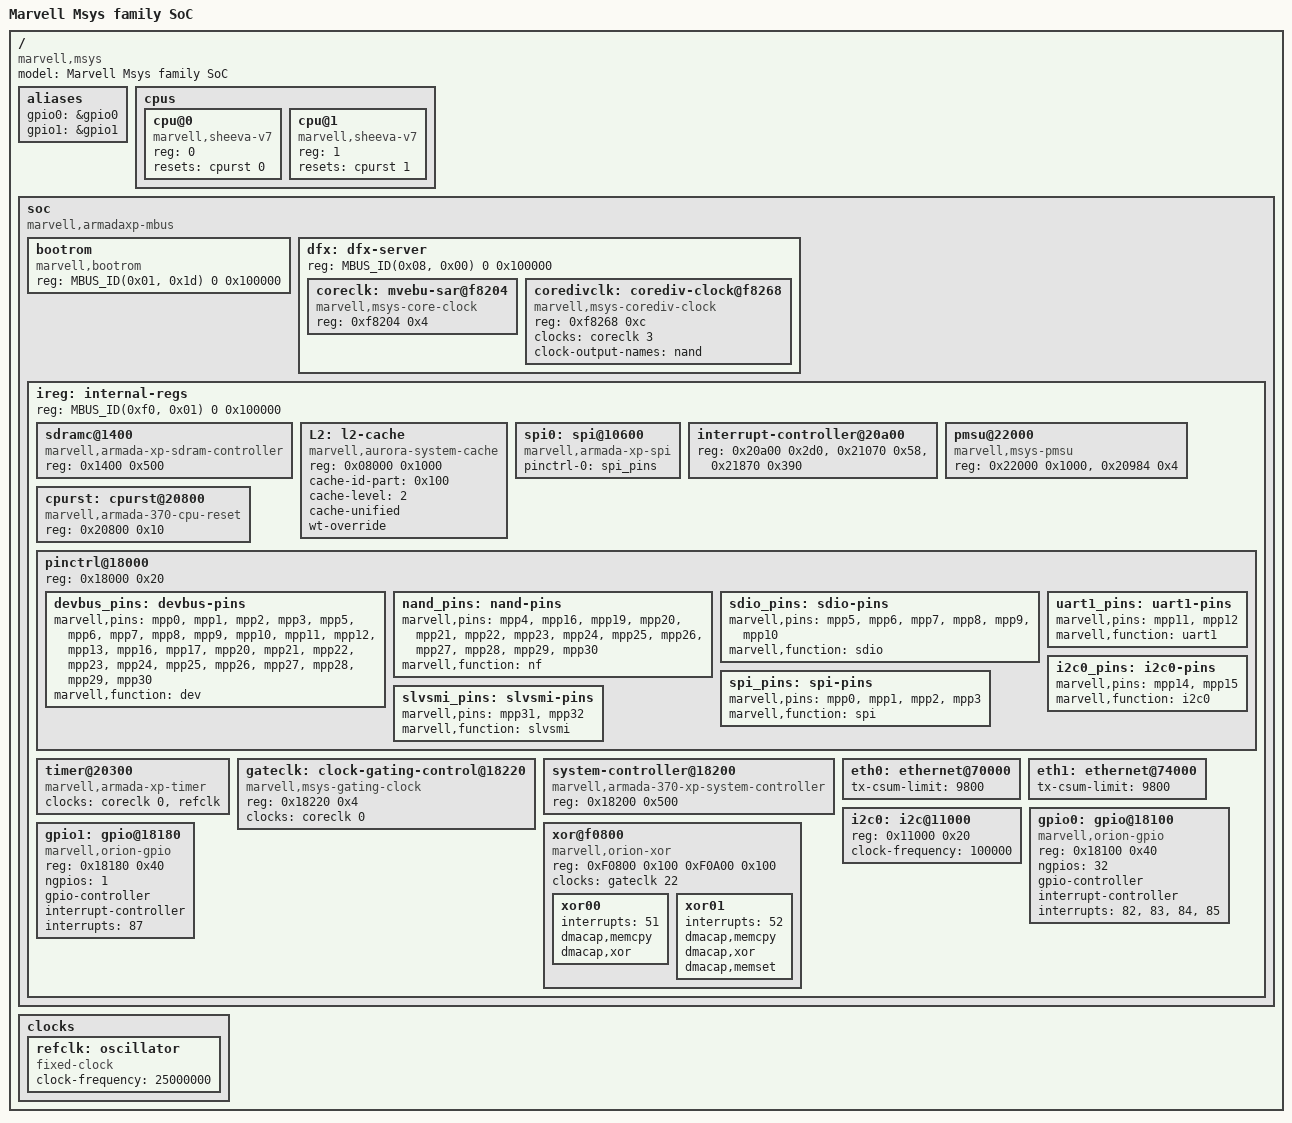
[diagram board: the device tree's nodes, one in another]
/*
 * Device Tree Include file for Marvell Msys family SoC
 *
 * Copyright (C) 2015 Marvell
 *
 * This file is licensed under the terms of the GNU General Public
 * License version 2.  This program is licensed "as is" without any
 * warranty of any kind, whether express or implied.
 *
 * Contains definitions specific to the Msys SoC that are not
 * common to all Armada SoCs.
 */

#include "armada-370-xp.dtsi"

/ {
	model = "Marvell Msys family SoC";
	compatible = "marvell,msys", "marvell,armada-370-xp";

	aliases {
		gpio0 = &gpio0;
		gpio1 = &gpio1;
	};

	cpus {
		#address-cells = <1>;
		#size-cells = <0>;

		cpu@0 {
			device_type = "cpu";
			compatible = "marvell,sheeva-v7";
			reg = <0>;
			resets = <&cpurst 0>;
		};

		cpu@1 {
			device_type = "cpu";
			compatible = "marvell,sheeva-v7";
			reg = <1>;
			resets = <&cpurst 1>;
		};
	};

	soc {
		compatible = "marvell,armadaxp-mbus", "simple-bus";

		bootrom {
			compatible = "marvell,bootrom";
			reg = <MBUS_ID(0x01, 0x1d) 0 0x100000>;
		};

		dfx: dfx-server {
			#address-cells = <1>;
			#size-cells = <1>;
			ranges = <0 MBUS_ID(0x08, 0x00) 0 0x100000>;
			reg = <MBUS_ID(0x08, 0x00) 0 0x100000>;

			coreclk: mvebu-sar@f8204 {
				compatible = "marvell,msys-core-clock";
				reg = <0xf8204 0x4>;
				#clock-cells = <1>;
			};

			coredivclk: corediv-clock@f8268 {
				compatible = "marvell,msys-corediv-clock";
				reg = <0xf8268 0xc>;
				#clock-cells = <1>;
				clocks = <&coreclk 3>;
				clock-output-names = "nand";
			};
		};

		ireg: internal-regs {
			reg = <MBUS_ID(0xf0, 0x01) 0 0x100000>;

			sdramc@1400 {
				compatible = "marvell,armada-xp-sdram-controller";
				reg = <0x1400 0x500>;
			};

			L2: l2-cache {
				compatible = "marvell,aurora-system-cache";
				reg = <0x08000 0x1000>;
				cache-id-part = <0x100>;
				cache-level = <2>;
				cache-unified;
				wt-override;
			};

			spi0: spi@10600 {
				compatible = "marvell,armada-xp-spi",
						"marvell,orion-spi";
				pinctrl-0 = <&spi_pins>;
				pinctrl-names = "default";
			};

			interrupt-controller@20a00 {
			      reg = <0x20a00 0x2d0>, <0x21070 0x58>, <0x21870 0x390>;
			};

			pmsu@22000 {
				compatible = "marvell,msys-pmsu";
				reg = <0x22000 0x1000>, <0x20984 0x4>;
			};

			cpurst: cpurst@20800 {
				compatible = "marvell,armada-370-cpu-reset";
				reg = <0x20800 0x10>;
				#reset-cells = <1>;
			};

			pinctrl@18000 {
				reg = <0x18000 0x20>;

				devbus_pins: devbus-pins {
					marvell,pins = "mpp0", "mpp1", "mpp2",
									"mpp3", "mpp5", "mpp6",
									"mpp7", "mpp8", "mpp9",
									"mpp10", "mpp11", "mpp12",
									"mpp13", "mpp16", "mpp17",
									"mpp20", "mpp21", "mpp22",
									"mpp23", "mpp24", "mpp25",
									"mpp26", "mpp27", "mpp28",
									"mpp29", "mpp30";
					marvell,function = "dev";
				};

				nand_pins: nand-pins {
					marvell,pins = "mpp4", "mpp16", "mpp19",
									"mpp20", "mpp21", "mpp22",
									"mpp23", "mpp24", "mpp25",
									"mpp26", "mpp27", "mpp28",
									"mpp29", "mpp30";
					marvell,function = "nf";
				};

				sdio_pins: sdio-pins {
					marvell,pins = "mpp5", "mpp6", "mpp7",
									"mpp8", "mpp9", "mpp10";
					marvell,function = "sdio";
				};

				spi_pins: spi-pins {
					marvell,pins = "mpp0", "mpp1", "mpp2",
									"mpp3";
					marvell,function = "spi";
				};

				uart1_pins: uart1-pins {
					marvell,pins = "mpp11", "mpp12";
					marvell,function = "uart1";
				};

				i2c0_pins: i2c0-pins {
					marvell,pins = "mpp14", "mpp15";
					marvell,function = "i2c0";
				};

				slvsmi_pins: slvsmi-pins {
					marvell,pins = "mpp31", "mpp32";
					marvell,function = "slvsmi";
				};

			};

			timer@20300 {
				compatible = "marvell,armada-xp-timer";
				clocks = <&coreclk 0>, <&refclk>;
				clock-names = "nbclk", "fixed";
			};

			gateclk: clock-gating-control@18220 {
				compatible = "marvell,msys-gating-clock";
				reg = <0x18220 0x4>;
				clocks = <&coreclk 0>;
				#clock-cells = <1>;
			};

			system-controller@18200 {
				compatible = "marvell,armada-370-xp-system-controller";
				reg = <0x18200 0x500>;
			};

			/* Overwrite FIFO size */
			eth0: ethernet@70000 {
				tx-csum-limit = <9800>;
			};

			eth1: ethernet@74000 {
				tx-csum-limit = <9800>;
			};

			i2c0: i2c@11000 {
				reg = <0x11000 0x20>;
				status = "okay";
				clock-frequency = <100000>;
			};

			xor@f0800 {
				compatible = "marvell,orion-xor";
				reg = <0xF0800 0x100
				       0xF0A00 0x100>;
				clocks = <&gateclk 22>;
				status = "okay";

				xor00 {
					interrupts = <51>;
					dmacap,memcpy;
					dmacap,xor;
				};
				xor01 {
					interrupts = <52>;
					dmacap,memcpy;
					dmacap,xor;
					dmacap,memset;
				};
			};

			gpio0: gpio@18100 {
				compatible = "marvell,orion-gpio";
				reg = <0x18100 0x40>;
				ngpios = <32>;
				gpio-controller;
				#gpio-cells = <2>;
				interrupt-controller;
				#interrupt-cells = <2>;
				interrupts = <82>, <83>, <84>, <85>;
			};

			gpio1: gpio@18180 {
				compatible = "marvell,orion-gpio";
				reg = <0x18180 0x40>;
				ngpios = <1>;
				gpio-controller;
				#gpio-cells = <2>;
				interrupt-controller;
				#interrupt-cells = <2>;
				interrupts = <87>;
			};
		};

	};

	clocks {
		/* 25 MHz reference crystal */
		refclk: oscillator {
			compatible = "fixed-clock";
			#clock-cells = <0>;
			clock-frequency = <25000000>;
		};
	};
};
